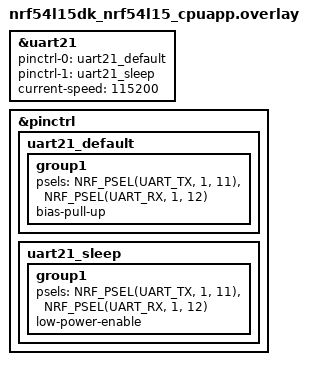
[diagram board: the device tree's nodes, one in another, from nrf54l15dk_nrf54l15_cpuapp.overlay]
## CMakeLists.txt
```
cmake_minimum_required(VERSION 3.20.0)
find_package(Zephyr REQUIRED HINTS $ENV{ZEPHYR_BASE})

project(Instabov_Eartag_Gateway)

target_sources(app PRIVATE 
        src/main.c
        src/ble/ble_scan.c
        src/peripherals/my_gpio.c
        src/peripherals/my_uart.c
        src/app.c
        src/libs/cobs.c
)
```

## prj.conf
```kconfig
#Enable Printk
CONFIG_PRINTK=y

#Enable GPIO
CONFIG_GPIO=y

#Include the Bluetooth LE stack
CONFIG_BT=y

#Configure the device to operate in the LE Central role.
CONFIG_BT_CENTRAL=y

#Configure scan parameters
CONFIG_BT_SCAN=y
CONFIG_BT_SCAN_FILTER_ENABLE=y
CONFIG_BT_SCAN_NAME_CNT=5
CONFIG_BT_SCAN_UUID_CNT=5

#Enable extended advertising
CONFIG_BT_EXT_ADV=y
CONFIG_BT_CTLR_PHY_CODED=y
CONFIG_BT_EXT_ADV_CODING_SELECTION=y


# Increase stack size for the main thread and System Workqueue
CONFIG_SYSTEM_WORKQUEUE_STACK_SIZE=2048
CONFIG_MAIN_STACK_SIZE=4096
CONFIG_BT_RX_STACK_SIZE=2048
CONFIG_HEAP_MEM_POOL_SIZE=2048

# Enable UART drivers
CONFIG_SERIAL=y
CONFIG_UART_ASYNC_API=y
CONFIG_UART_USE_RUNTIME_CONFIGURE=y
CONFIG_NRFX_UARTE=y

# Date time library
CONFIG_POSIX_API=y
CONFIG_POSIX_TIMERS=y
CONFIG_NEWLIB_LIBC=y

# CRC-32 Library
CONFIG_CRC=y

# Add support to MURMUR3 hash function
CONFIG_SYS_HASH_FUNC32_MURMUR3=y



#Just used with nRF21540
#CONFIG_MPSL=y
#CONFIG_MPSL_FEM=y
#CONFIG_MPSL_FEM_NRF21540_RX_GAIN_DB=13
```

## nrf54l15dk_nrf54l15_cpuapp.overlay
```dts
// To get started, press Ctrl+Space to bring up the completion menu and view the available nodes.

// You can also use the buttons in the sidebar to perform actions on nodes.
// Actions currently available include:

// * Enabling / disabling the node
// * Adding the bus to a bus
// * Removing the node
// * Connecting ADC channels

// For more help, browse the DeviceTree documentation at https://docs.zephyrproject.org/latest/guides/dts/index.html
// You can also visit the nRF DeviceTree extension documentation at https://docs.nordicsemi.com/bundle/nrf-connect-vscode/page/guides/ncs_configure_app.html#devicetree-support-in-the-extension
&uart21 {
    status = "okay";
    pinctrl-0 = <&uart21_default>;
	pinctrl-1 = <&uart21_sleep>;
	pinctrl-names = "default", "sleep";
    current-speed = <115200>;
};


&pinctrl {
    uart21_default: uart21_default{
        group1{
            psels = <NRF_PSEL(UART_TX, 1, 11)>,
                    <NRF_PSEL(UART_RX, 1, 12)>;
            bias-pull-up;
        };
    };

    uart21_sleep: uart21_sleep{
        group1{
            psels = <NRF_PSEL(UART_TX, 1, 11)>,
                    <NRF_PSEL(UART_RX, 1, 12)>;
            low-power-enable;
        };
    };
};
```

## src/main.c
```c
#include <zephyr/kernel.h>
#include "ble/ble_scan.h"
#include "peripherals/my_gpio.h"
#include "app.h"
#include "peripherals/my_uart.h"

int err;

int main(void)
{
	//Configure buttons and LEDs
	configure_my_gpio();

	err = my_uart_initialize();
	if(err){
		sprintf(debug_str, "UART Error: %d", err);
	}

	//Initialize BLE stack
	bt_enable(NULL);

	//Configure scan parameters
	init_scan_module();

	//Start scannning
	err = bt_scan_start(BT_SCAN_TYPE_SCAN_PASSIVE);
	if(err){
		printk("err=%d\r\n", err);
	}
	printk("oi\r\n");

	cobs_pkt.idx = 0;
    
	
	//Enable UART reception
	uart_rx_enable(my_uart, rx_buf.a, sizeof(rx_buf.a), 10000);
    rx_buf.a_busy = true;

	if(err){
		sprintf(debug_str, "UART Error: %d", err);
	}

	while(1){
		app_state_machine();
		debug_print_table();
	}
    return 0;
}
```

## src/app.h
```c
#ifndef APP_H
#define APP_H
#include <zephyr/kernel.h>
#include <zephyr/bluetooth/bluetooth.h>
#include <zephyr/bluetooth/uuid.h>
#include <bluetooth/scan.h>
#include "peripherals/my_gpio.h"
#include <string.h>
#include <time.h>
#include <zephyr/sys/crc.h>
#include "app_config.h"
#include <zephyr/sys/hash_function.h>
#include "libs/cobs.h"



//Debug GUI
#define ERASE_DISPLAY printk("\033[H\033[0J")
#define GO_HOME_DISPLAY printk("\033[H")
#define CURSOR_UP_DISPLAY(x) printk("\033[%dA",x)
#define CURSOR_DOWN_DISPLAY(x) printk("\033[%dB",x)
#define CURSOR_RIGHT_DISPLAY(x) printk("\033[%dC",x)
#define CURSOR_LEFT_DISPLAY(x) printk("\033[%dD",x)
#define CURSOR_GO_TO_DISPLAY(x,y) printk("\033[%d;%dH", x, y)
#define SET_COLOR_DISPLAY(r,g,b) printk("\033[38;2;%d;%d;%dm",r,g,b)
#define SET_BG_COLOR_DISPLAY(r,g,b) printk("\033[48;2;%d;%d;%dm",r,g,b)

extern volatile char debug_str[100];
extern volatile bool just_once_debug;

#define EARTAG_TABLE_SIZE 1000

//Application State Machine states definition
typedef enum{
    fetching_procedures,
    time_sync,
    time_sync_wait_tx,
    table_xfer,
    table_xfer_wait_tx,
    table_xfer_wait_ack,
    table_housekeeping_start,
    error_procedure,
    error_procedure_wait_tx,
}states_type;

extern volatile states_type state;

// Queue used by ISRs to submit procedure requests for processing by the application state machine
extern struct k_msgq procedure_queue;

// Procedures enumeration
typedef enum{
    none,
    time_sync_proc,
    table_xfer_proc,
    table_housekeeping_proc,
    error_proc,
} procedures_t;

// Variable used to post procedure requests
extern volatile procedures_t procedure_request;

// Structure holding all data related to a single received advertising packet
typedef struct{
    int8_t rssi;
    uint8_t mac_addr[6];
    uint8_t bat;
    uint32_t steps;
}eartag_type;

extern volatile eartag_type eartag;

// Union used to pack battery level and step count into a single 32-bit value
// - Battery level: 8 bits
// - Step count: 24 bits
typedef union{
	uint32_t value;
	struct{
		uint32_t bat : 8;
		uint32_t step : 24;
	} __attribute__((packed)) field;
} custom_data_type;

//flags inside delta_flag
#define TIME_FLAG       (1u << 0)
#define ID_FLAG         (1u << 1)
#define STEP_FLAG       (1u << 2)
#define BAT_FLAG        (1u << 3)
#define RSSI_FLAG       (1u << 4)


// Structure representing a single entry in the eartag table
typedef struct{
    uint32_t unix_time;
    uint8_t eartag_id[6];
    custom_data_type bat_step;
    int8_t rssi;
}__attribute__((packed)) table_entry_type;

// Eartag table storage
extern volatile table_entry_type eartag_table[EARTAG_TABLE_SIZE];

// Snapshot of the eartag table at the time of the last transmission
extern volatile table_entry_type last_tx_eartag_table[EARTAG_TABLE_SIZE];

// Index of the first available entry in the eartag table
extern volatile uint16_t current_idx;

// Index of the first available entry in the eartag table at the time of the last transmission
extern volatile uint16_t last_tx_current_idx;

// Union for accessing the individual bytes of a uint32_t variable
typedef union{
    uint32_t value;
    struct{
        uint8_t byte[4];
    }__attribute__((packed)) bytes;
}my_uint32_t;

// Standard UART packet structure
typedef union{
    uint8_t frame[5]__attribute__((packed));
    struct{
        uint8_t opcode;
        my_uint32_t payload;
    }__attribute__((packed)) field;
}std_uart_pkt_type;

// Structure used for transmitting the eartag table 
typedef union{
    uint8_t frame[(EARTAG_TABLE_SIZE*14)+16]__attribute__((packed));
    struct{
        uint8_t opcode;
        my_uint32_t crc32;
        uint16_t n_of_entries;
        my_uint32_t base_timestamp;
        my_uint32_t base_step_counter;
        uint8_t delta_step_counter_len;
        uint8_t delta_payload[EARTAG_TABLE_SIZE*14]__attribute__((packed));
    }__attribute__((packed)) field;
}delta_frame_t;

// Structure used to store all types of data packets (some overhead is added for COBS enconding)
typedef struct{
    uint8_t buf[(EARTAG_TABLE_SIZE*14)+16+1000]__attribute__((packed));
    uint16_t idx;
}generic_dat_pkt_t;

// Generic buffer used to store both standard and delta packets
extern volatile generic_dat_pkt_t data_pkt;

// Pointer used to cast the generic packet to a standard packet
extern const std_uart_pkt_type *std_pkt;

// UART RX/TX buffer for COBS-encoded packets.
// The size accounts for the maximum eartag table payload plus COBS overhead and safety margin.
extern volatile generic_dat_pkt_t cobs_pkt;

// Standard TX UART packet instance
extern volatile std_uart_pkt_type std_uart_packet_tx;

// Structure used for transmitting the eartag table
extern volatile delta_frame_t delta_table_packet;

// Size of the table to be transmitted, in bytes
extern volatile uint32_t delta_table_pkt_len;

//UART opcodes
#define TIME_SYNC_CMD 0x09
#define TABLE_REQ_CMD 0x0A
#define TABLE_LEN_RES 0x0B
#define OK_RES 0x0C
#define NOK_RES 0x0D
#define TABLE_RES 0x0E

//NOK reason codes
#define TABLE_REQ_ERROR 0x0F
#define TIME_SYNC_ERROR 0x10
#define PKT_MALFORMED_ERROR 0x11
#define PKT_OVERFLOW_ERROR 0x12


// Bit positions of the events.
#define EVT_TIME_SYNC                   (1u << 0)
#define EVT_OK_RCVD                     (1u << 1)
#define EVT_NOK_RCVD                    (1u << 2)
#define EVT_STD_PKT_RCVD                (1u << 3)
#define EVT_DELTA_PKT_RCVD              (1u << 4)
#define EVT_UART_TIMEOUT                (1u << 5)
#define EVT_UART_PKT_RCVD               (1u << 6)
#define EVT_UART_PKT_OVERFLOW           (1u << 7)
#define EVT_UART_NO_BUF                 (1u << 8)
#define EVT_UART_NO_BUF_DISABLED        (1u << 9)
#define EVT_UART_RX_BUSY_DROPPED        (1u << 10)
#define EVT_UART_FRAME_GAP_VIOLATION    (1u << 10)
#define EVT_APP_RCVD_PKT_ERR            (1u << 11)
#define EVT_APP_UART_ERR                (1u << 12)
#define EVT_ERR                         (1u << 13)
#define EVT_TX_DONE                     (1u << 14)

// Event object used for inter-thread and ISR signaling
extern struct k_event app_evt;

// Enumeration defining the possible error causes reported by the system
typedef enum{
    err_none,
    err_uart_no_buf,
    err_uart_disabled,
    err_gap_violation,
    err_pkt_overflow,
    err_uart_busy_dropped,
    err_pkt_malformed
}err_codes_t;

// Structure holding the current error status and its severity level
typedef struct{
    err_codes_t err_code;
    uint8_t severity;
}err_var_t;

// Global variable that stores the most recently reported error that has not yet been processed, along with its severity level
extern volatile err_var_t err_var;

// Semaphore that triggers the execution of cmd_res_handler()
extern struct k_sem run_cmd_res_handler;

// Current Unix timestamp (seconds since epoch)
extern volatile uint32_t current_unix_time;

//UTC date/time structure
extern volatile struct tm utc_date;

//Current Unix Timestamp
extern volatile struct timespec current_ts;

// Timer used to restart the UART in case of a timeout
extern struct k_timer uart_timeout;

// Counter used to schedule and control network time synchronization events
extern volatile uint32_t net_sync_counter;

// Message queue shared between the scan ISR and eartag_table_handler(): 
// the ISR enqueues received eartags, and the handler inserts them into the eartag table
extern struct k_msgq eartag_msg_queue;

// This flag prevents new entries from being added to the eartag table during critical operations
extern volatile atomic_t table_freeze;

// This flag prevents data from being added to data_pkt while it is being processed
extern volatile atomic_t data_pkt_freeze;

// Semaphore used by add_to_table() to notify that an entry has been removed from the table
extern struct k_sem entry_removed_sem;

// Unix timer resolution, in milliseconds
#define UNIX_TIMER_RESOLUTION_MS 5000

// Interval between consecutive network time synchronization operations, in milliseconds
#define NET_TIME_SYNC_PERIOD_MS 120000

// UART timeout callback function
void uart_timeout_cb(struct k_timer *timer_id);

// Procedure timeout callback function
void procedure_timeout_cb(struct k_timer *timer_id);

// Table housekeeping callback function
void table_housekeeping_cb(struct k_timer *timer_id);

// Adds an entry to the eartag table, or updates it if the same ID already exists
int add_to_table(eartag_type *ear_tag);

// Checks whether the provided MAC address already exists in the eartag table.
// Returns the corresponding index if found, or -1 if it does not exist.
int exists_in_table(uint8_t *mac_hex);

// Compare the current eartag table with the last transmitted one and format the provided delta frame accordingly
// If send_all is set, all fields are transmitted; otherwise, only fields that changed since the last transmission are included
// Returns 0 on success, or -1 on failure
int format_delta_packet(delta_frame_t *df, bool send_all);

// Used to notify the main application of the occurrence of one or more errors.
// It sets the error code and pushes the error_procedure to the procedure_queue.
// Depending on the error severity, all pending procedures are flushed before
// inserting the error procedure.
int post_error(err_codes_t error_code);

// Helper function that formats a TX packet, encodes it using the COBS protocol,
// appends a delimiter, and sends it through the UART
// Returns 0 on success; negative values indicate an error
int send_cobs_uart_pkt(uint8_t opcode, uint8_t *payload, size_t pkt_len);

// Application state machine
void app_state_machine(void);

// Function responsible for printing the current table to the terminal
void debug_print_table(void);

// Formats a number into a string of fixed length (char_size), centering the number
// and padding the remaining characters as needed.
int debug_centralize_str_num(char *out_str, uint32_t number, uint8_t char_size);

#endif
```

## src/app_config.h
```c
#ifndef APP_CONFIG_H
#define APP_CONFIG_H

#define TOO_OLD_EARTAG_HOURS 8


#endif
```
